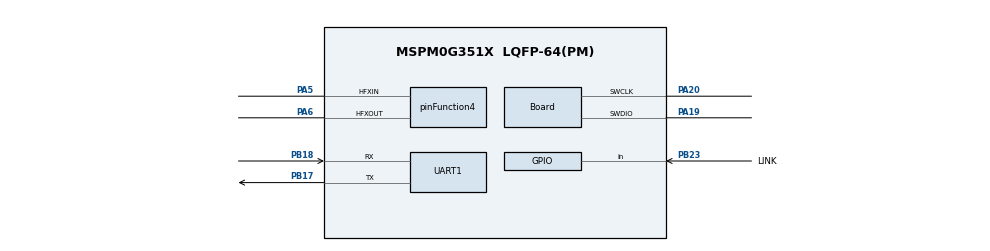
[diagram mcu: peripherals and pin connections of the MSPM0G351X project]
/**
 * @cliArgs --device "MSPM0G351X" --part "Default" --package "LQFP-64(PM)" --product "mspm0_sdk@2.05.01.01"
 * @versions {"tool":"1.24.0+4110"}
 */

const GPIO   = scripting.addModule("/ti/driverlib/GPIO", {}, false);
const GPIO1  = GPIO.addInstance();
const SYSCTL = scripting.addModule("/ti/driverlib/SYSCTL");
const UART   = scripting.addModule("/ti/driverlib/UART", {}, false);
const UART1  = UART.addInstance();

/* 80 MHz clock */
SYSCTL.forceDefaultClkConfig = true;
SYSCTL.clockTreeEn           = true;
scripting.suppress("For best practices when the CPUCLK is running at 32MHz and above, clear the flash status bit using DL_FlashCTL_executeClearStatus\\(\\) before executing any flash operation\\. Otherwise there may be false positives\\.", SYSCTL);

const divider9       = system.clockTree["UDIV"];
divider9.divideValue = 2;
const multiplier2         = system.clockTree["PLL_QDIV"];
multiplier2.multiplyValue = 4;
const mux4       = system.clockTree["EXHFMUX"];
mux4.inputSelect = "EXHFMUX_XTAL";
const mux8       = system.clockTree["HSCLKMUX"];
mux8.inputSelect = "HSCLKMUX_SYSPLL0";
const mux12       = system.clockTree["SYSPLLMUX"];
mux12.inputSelect = "zSYSPLLMUX_HFCLK";
const pinFunction4                        = system.clockTree["HFXT"];
pinFunction4.inputFreq                    = 40;
pinFunction4.enable                       = true;
pinFunction4.HFXTStartup                  = 10;
pinFunction4.HFCLKMonitor                 = true;
pinFunction4.peripheral.$assign           = "SYSCTL";
pinFunction4.peripheral.hfxInPin.$assign  = "PA5";
pinFunction4.peripheral.hfxOutPin.$assign = "PA6";

/* Board: SWD */
const Board                       = scripting.addModule("/ti/driverlib/Board", {}, false);
Board.peripheral.$assign          = "DEBUGSS";
Board.peripheral.swclkPin.$assign = "PA20";
Board.peripheral.swdioPin.$assign = "PA19";

/* Wireless link status: PB23 input */
GPIO1.$name                          = "WIRELESS";
GPIO1.associatedPins[0].$name        = "LINK";
GPIO1.associatedPins[0].direction    = "INPUT";
GPIO1.associatedPins[0].assignedPort = "PORTB";
GPIO1.associatedPins[0].assignedPin  = "23";
GPIO1.associatedPins[0].internalResistor = "PULL_DOWN";
GPIO1.associatedPins[0].pin.$assign  = "PB23";

/* UART7: PB17(TX) / PB18(RX) */
UART1.$name                            = "UART_WIRELESS";
UART1.enabledInterrupts                = ["RX"];
UART1.peripheral.$assign               = "UART7";
UART1.peripheral.rxPin.$assign         = "PB18";
UART1.peripheral.txPin.$assign         = "PB17";
UART1.txPinConfig.direction            = scripting.forceWrite("OUTPUT");
UART1.txPinConfig.hideOutputInversion  = scripting.forceWrite(false);
UART1.txPinConfig.onlyInternalResistor = scripting.forceWrite(false);
UART1.txPinConfig.passedPeripheralType = scripting.forceWrite("Digital");
UART1.rxPinConfig.hideOutputInversion  = scripting.forceWrite(false);
UART1.rxPinConfig.onlyInternalResistor = scripting.forceWrite(false);
UART1.rxPinConfig.passedPeripheralType = scripting.forceWrite("Digital");

const ProjectConfig              = scripting.addModule("/ti/project_config/ProjectConfig", {}, false);
ProjectConfig.migrationCondition = true;
